VERSION ""

NS_ :

BS_:

BU_: INV AIM

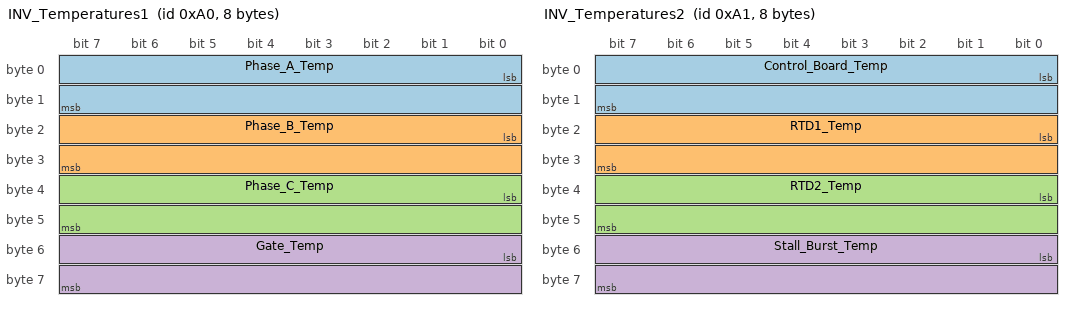
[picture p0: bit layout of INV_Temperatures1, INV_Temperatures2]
BO_ 160 INV_Temperatures1: 8 INV
 SG_ Phase_A_Temp : 0|16@1- (0.1,0) [-3276.8|3276.7] "degC" AIM
 SG_ Phase_B_Temp : 16|16@1- (0.1,0) [-3276.8|3276.7] "degC" AIM
 SG_ Phase_C_Temp : 32|16@1- (0.1,0) [-3276.8|3276.7] "degC" AIM
 SG_ Gate_Temp : 48|16@1- (0.1,0) [-3276.8|3276.7] "degC" AIM

BO_ 161 INV_Temperatures2: 8 INV
 SG_ Control_Board_Temp : 0|16@1- (0.1,0) [-3276.8|3276.7] "degC" AIM
 SG_ RTD1_Temp : 16|16@1- (0.1,0) [-3276.8|3276.7] "degC" AIM
 SG_ RTD2_Temp : 32|16@1- (0.1,0) [-3276.8|3276.7] "degC" AIM
 SG_ Stall_Burst_Temp : 48|16@1- (0.1,0) [-3276.8|3276.7] "degC" AIM

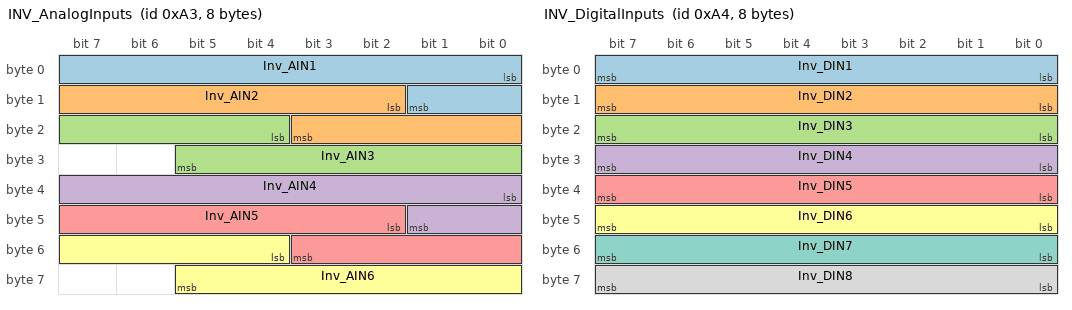
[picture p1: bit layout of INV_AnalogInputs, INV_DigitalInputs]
BO_ 163 INV_AnalogInputs: 8 INV
 SG_ Inv_AIN1 : 0|10@1+ (0.01,0) [0|10.23] "V" AIM
 SG_ Inv_AIN2 : 10|10@1+ (0.01,0) [0|10.23] "V" AIM
 SG_ Inv_AIN3 : 20|10@1+ (0.01,0) [0|10.23] "V" AIM
 SG_ Inv_AIN4 : 32|10@1+ (0.01,0) [0|10.23] "V" AIM
 SG_ Inv_AIN5 : 42|10@1+ (0.01,0) [0|10.23] "V" AIM
 SG_ Inv_AIN6 : 52|10@1+ (0.01,0) [0|10.23] "V" AIM

BO_ 164 INV_DigitalInputs: 8 INV
 SG_ Inv_DIN1 : 0|8@1+ (1,0) [0|255] "" AIM
 SG_ Inv_DIN2 : 8|8@1+ (1,0) [0|255] "" AIM
 SG_ Inv_DIN3 : 16|8@1+ (1,0) [0|255] "" AIM
 SG_ Inv_DIN4 : 24|8@1+ (1,0) [0|255] "" AIM
 SG_ Inv_DIN5 : 32|8@1+ (1,0) [0|255] "" AIM
 SG_ Inv_DIN6 : 40|8@1+ (1,0) [0|255] "" AIM
 SG_ Inv_DIN7 : 48|8@1+ (1,0) [0|255] "" AIM
 SG_ Inv_DIN8 : 56|8@1+ (1,0) [0|255] "" AIM

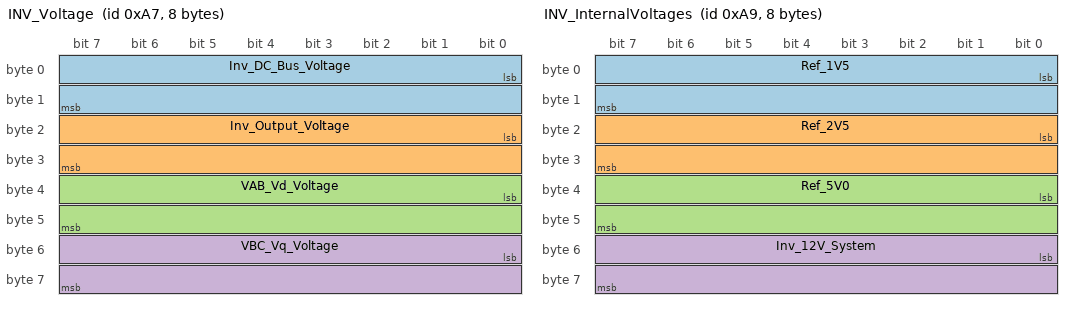
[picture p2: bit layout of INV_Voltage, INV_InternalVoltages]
BO_ 167 INV_Voltage: 8 INV
 SG_ Inv_DC_Bus_Voltage : 0|16@1- (0.1,0) [-3276.8|3276.7] "V" AIM
 SG_ Inv_Output_Voltage : 16|16@1- (0.1,0) [-3276.8|3276.7] "V" AIM
 SG_ VAB_Vd_Voltage : 32|16@1- (0.1,0) [-3276.8|3276.7] "V" AIM
 SG_ VBC_Vq_Voltage : 48|16@1- (0.1,0) [-3276.8|3276.7] "V" AIM

BO_ 169 INV_InternalVoltages: 8 INV
 SG_ Ref_1V5 : 0|16@1- (0.01,0) [-327.68|327.67] "V" AIM
 SG_ Ref_2V5 : 16|16@1- (0.01,0) [-327.68|327.67] "V" AIM
 SG_ Ref_5V0 : 32|16@1- (0.01,0) [-327.68|327.67] "V" AIM
 SG_ Inv_12V_System : 48|16@1- (0.01,0) [-327.68|327.67] "V" AIM

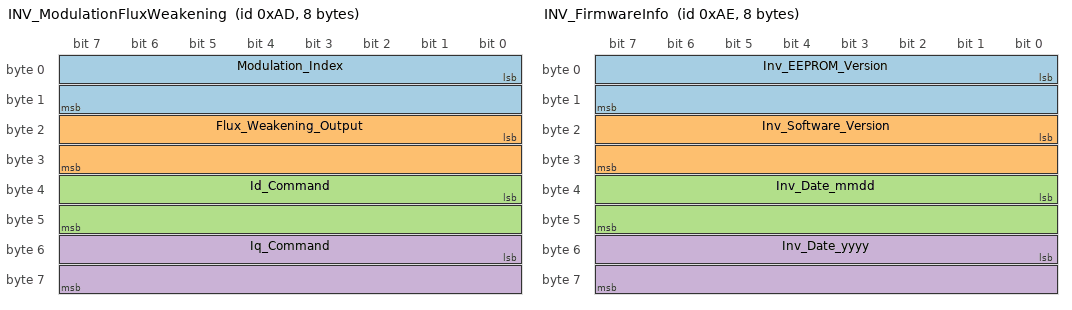
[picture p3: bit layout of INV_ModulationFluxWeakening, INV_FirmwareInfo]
BO_ 173 INV_ModulationFluxWeakening: 8 INV
 SG_ Modulation_Index : 0|16@1+ (0.01,0) [0|655.35] "" AIM
 SG_ Flux_Weakening_Output : 16|16@1- (0.1,0) [-3276.8|3276.7] "A" AIM
 SG_ Id_Command : 32|16@1- (0.1,0) [-3276.8|3276.7] "A" AIM
 SG_ Iq_Command : 48|16@1- (0.1,0) [-3276.8|3276.7] "A" AIM

BO_ 174 INV_FirmwareInfo: 8 INV
 SG_ Inv_EEPROM_Version : 0|16@1+ (1,0) [0|65535] "" AIM
 SG_ Inv_Software_Version : 16|16@1+ (1,0) [0|65535] "" AIM
 SG_ Inv_Date_mmdd : 32|16@1+ (1,0) [0|65535] "" AIM
 SG_ Inv_Date_yyyy : 48|16@1+ (1,0) [0|65535] "" AIM

CM_ "Inverter frames turned off in the current tune (CAN_ACTIVE_MSGS). Add to the AiM only after enabling them.";
CM_ BO_ 160 "Turned off in the inverter tune, needs its CAN_ACTIVE_MSGS Lo bit set (bit 0). RS3 had this on 0xA2 by mistake";
CM_ BO_ 161 "Turned off in the inverter tune, needs its CAN_ACTIVE_MSGS Lo bit set (bit 1)";
CM_ SG_ 161 Stall_Burst_Temp "Power module junction estimate";
CM_ BO_ 163 "Turned off in the inverter tune, needs its CAN_ACTIVE_MSGS Lo bit set (bit 3)";
CM_ BO_ 164 "Turned off in the inverter tune, needs its CAN_ACTIVE_MSGS Lo bit set (bit 4)";
CM_ BO_ 167 "Turned off in the inverter tune, needs its CAN_ACTIVE_MSGS Lo bit set (bit 7)";
CM_ SG_ 167 Inv_Output_Voltage "Peak line-neutral";
CM_ SG_ 167 VAB_Vd_Voltage "VAB when disabled, Vd when enabled";
CM_ SG_ 167 VBC_Vq_Voltage "VBC when disabled, Vq when enabled";
CM_ BO_ 169 "Turned off in the inverter tune, needs its CAN_ACTIVE_MSGS Lo bit set (bit 9)";
CM_ BO_ 173 "Turned off in the inverter tune, needs its CAN_ACTIVE_MSGS Lo bit set (bit 13)";
CM_ BO_ 174 "Turned off in the inverter tune, needs its CAN_ACTIVE_MSGS Lo bit set (bit 14)";

BA_DEF_ BO_ "GenMsgCycleTime" INT 0 65535;
BA_DEF_DEF_ "GenMsgCycleTime" 0;
BA_ "GenMsgCycleTime" BO_ 160 100;
BA_ "GenMsgCycleTime" BO_ 161 100;
BA_ "GenMsgCycleTime" BO_ 163 5;
BA_ "GenMsgCycleTime" BO_ 164 5;
BA_ "GenMsgCycleTime" BO_ 167 5;
BA_ "GenMsgCycleTime" BO_ 169 100;
BA_ "GenMsgCycleTime" BO_ 173 5;
BA_ "GenMsgCycleTime" BO_ 174 100;
